# ATSAMRH707F18A device description
Architecture: CORTEX-M7; Family: SAMRH; Series: SAMRH707
Registers are 32-bit, read-write, no defined reset value unless marked. A register's access mark holds for its fields unless they carry their own. Offsets are from the block's base; [hi:lo] are bit positions; lines under a group give offsets from that group; {n}, {i} and the like mark numbered series; 'fields as' and 'values as' point back to an identical list.

## HSMC — Harden Static Memory Controller
Instances: HSMC 0x40081000
{0x0+0x10*i} HSMC_CS[{i}] (i=0..1) group
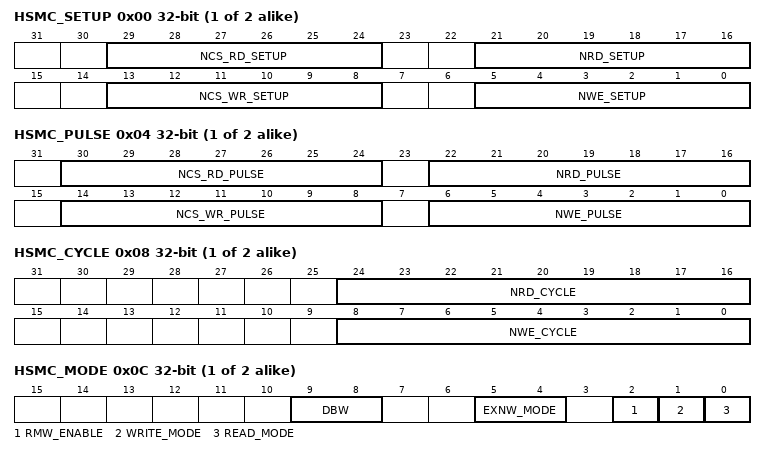
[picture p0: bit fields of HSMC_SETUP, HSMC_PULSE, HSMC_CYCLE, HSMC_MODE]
  0x00 HSMC_SETUP
    [29:24] NCS_RD_SETUP — NCS Setup Length in READ Access
    [21:16] NRD_SETUP — NRD Setup Length
    [13:8] NCS_WR_SETUP — NCS Setup Length in WRITE Access
    [5:0] NWE_SETUP — NWE Setup Length
  0x04 HSMC_PULSE
    [30:24] NCS_RD_PULSE — NCS Pulse Length in READ Access
    [22:16] NRD_PULSE — NRD Pulse Length
    [14:8] NCS_WR_PULSE — NCS Pulse Length in WRITE Access
    [6:0] NWE_PULSE — NWE Pulse Length
  0x08 HSMC_CYCLE
    [24:16] NRD_CYCLE — Total Read Cycle Length
    [8:0] NWE_CYCLE — Total Write Cycle Length
  0x0C HSMC_MODE
    [9:8] DBW — Data Bus Width
      0=_8_BIT (8-bit Data Bus)
    [5:4] EXNW_MODE — NWAIT Mode
      0=DISABLED (Disabled-The NWAIT input signal is ignored on the corresponding chip select.); 2=FROZEN (Frozen Mode-If asserted, the NWAIT signal freezes the current read or write cycle. After deassertion, the read/write cycle is resumed from the point where it was stopped.); 3=READY (Ready Mode-The NWAIT signal indicates the availability of the external device at the end of the pulse of the controlling read or write signal, to complete the access. If high, the access normally completes. If low, the access is extended until NWAIT returns high.)
    [2] RMW_ENABLE — Read-Modify Write enable
    [1] WRITE_MODE
    [0] READ_MODE
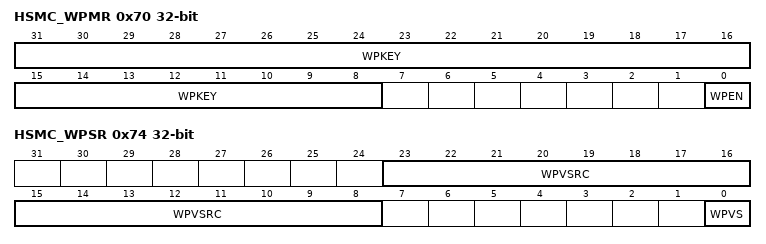
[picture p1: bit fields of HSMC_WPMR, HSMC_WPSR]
0x70 HSMC_WPMR — HSMC Write Protection Mode Register
  [31:8] WPKEY — Write Protection Key
    0x534D43=PASSWD (Writing any other value in this field aborts the write operation of the WPEN bit. Always reads as 0.)
  [0] WPEN — Write Protect Enable
0x74 HSMC_WPSR ro — HSMC Write Protection Status Register
  [23:8] WPVSRC — Write Protection Violation Source
  [0] WPVS — Write Protection Violation Status

## ICM_DESCRIPTOR — Region Descriptor Structure
0x00 RADDR — Region Start Address
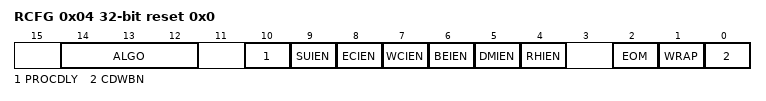
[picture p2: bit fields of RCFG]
0x04 RCFG reset 0x0 — Region Configuration
  [14:12] ALGO — SHA Algorithm
    0=SHA1 (SHA1 algorithm processed); 1=SHA256 (SHA256 algorithm processed); 4=SHA224 (SHA224 algorithm processed)
  [10] PROCDLY — SHA Processing Delay
    0=SHORT; 1=LONG
  [9] SUIEN — Region Status Updated Interrupt Enable
    0=EN; 1=DIS
  [8] ECIEN — Region End bit Condition detected Interrupt Enable
    0=EN; 1=DIS
  [7] WCIEN — Region Wrap Condition Detected Interrupt Enable
    0=EN; 1=DIS
  [6] BEIEN — Region Bus Error Interrupt Enable
    0=EN; 1=DIS
  [5] DMIEN — Region Digest Mismatch Interrupt Enable
    0=EN; 1=DIS
  [4] RHIEN — Region Hash Interrupt Enable
    0=EN; 1=DIS
  [2] EOM — End of Monitoring
    0=NO; 1=YES
  [1] WRAP — Region Wrap
    0=NO; 1=YES
  [0] CDWBN — Compare Digest Write Back
    0=WRBA; 1=COMP
0x08 RCTRL — Region Control
  [15:0] TRSIZE — Transfer Size for the Current Chunk of Data
0x0C RNEXT — Region Next Address
  [31:2] NEXT — Region Transfer Descriptor Next Address

## IP1553
Instances: IP1553 0x4003C000
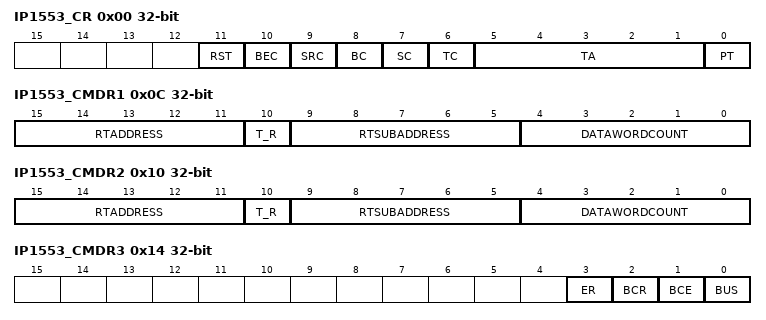
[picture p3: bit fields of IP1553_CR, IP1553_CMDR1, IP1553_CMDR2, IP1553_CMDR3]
0x00 IP1553_CR — Configuration Register
  [11] RST — Soft Reset
  [10] BEC — BCEnableCmd
  [9] SRC — SREQBitCmd
  [8] BC — BusyBitCmd
  [7] SC — SSBitCmd
  [6] TC — TRBitCmd
  [5:1] TA — TermAddressConf
  [0] PT — POTermConf
0x0C IP1553_CMDR1 wo — Command Register 1
  [15:11] RTADDRESS, [10] T_R, [9:5] RTSUBADDRESS, [4:0] DATAWORDCOUNT
0x10 IP1553_CMDR2 wo — Command Register 2
  [15:11] RTADDRESS
  [10] T_R — R/T
  [9:5] RTSUBADDRESS
  [4:0] DATAWORDCOUNT
0x14 IP1553_CMDR3 wo — Command Register 3
  [3] ER — data or command transfer
  [2] BCR — 1553 receiver
  [1] BCE — 1553 emitter
  [0] BUS — bus used
0x18 IP1553_BITR wo — BIT Register
  [15:0] TOBITWORD
0x1C IP1553_VWR wo — Vector Word Register
  [15:0] TOVECTORWORD
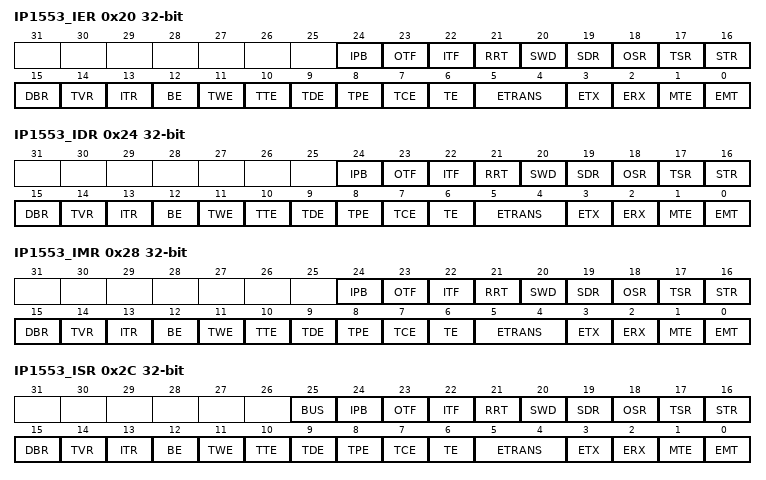
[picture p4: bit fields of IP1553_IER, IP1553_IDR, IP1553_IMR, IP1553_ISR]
0x20 IP1553_IER wo — IRQ Mask Enable Register
  [24] IPB — IPBusy
  [23] OTF — OvInhibitTermFlagReq
  [22] ITF — InhibitTermFlagReq
  [21] RRT — ResetRTReq
  [20] SWD — SyncWithoutDataReq
  [19] SDR — SyncWithDataReq
  [18] OSR — OvTranShutdownReq
  [17] TSR — TranShutdownReq
  [16] STR — InitSelfTestReq
  [15] DBR — DynamicBusContReq
  [14] TVR — TransVecWordReq
  [13] ITR — IllegalTransferReq
  [12] BE — BufIFErr
  [11] TWE — TransWordCounterErr
  [10] TTE — TransTimeOutErr
  [9] TDE — TransDataTypeErr
  [8] TPE — TransParityErr
  [7] TCE — TransCodingErr
  [6] TE — TransErr
  [5:4] ETRANS — EndTransfer
  [3] ETX — EndTransmission
  [2] ERX — End reception
  [1] MTE — MemTransferErr
  [0] EMT — EndMemTransfer
0x24 IP1553_IDR wo — IRQ Mask Disable Register
  fields as IP1553_IER
0x28 IP1553_IMR ro — IRQ Mask Register
  fields as IP1553_IER
0x2C IP1553_ISR ro — IRQ Status Register
  [25] BUS — BUS activated on last transfer
  [24] IPB — IPBusy
  [23] OTF — OvInhibitTermFlagReq
  [22] ITF — InhibitTermFlagReq
  [21] RRT — ResetRTReq
  [20] SWD — SyncWithoutDataReq
  [19] SDR — SyncWithDataReq
  [18] OSR — OvTranShutdownReq
  [17] TSR — TranShutdownReq
  [16] STR — InitSelfTestReq
  [15] DBR — DynamicBusContReq
  [14] TVR — TransVecWordReq
  [13] ITR — IllegalTransferReq
  [12] BE — BufIFErr
  [11] TWE — TransWordCounterErr
  [10] TTE — TransTimeOutErr
  [9] TDE — TransDataTypeErr
  [8] TPE — TransParityErr
  [7] TCE — TransCodingErr
  [6] TE — TransErr
  [5:4] ETRANS — EndTransfer
  [3] ETX — EndTransmission
  [2] ERX — End reception
  [1] MTE — MemTransferErr
  [0] EMT — EndMemTransfer
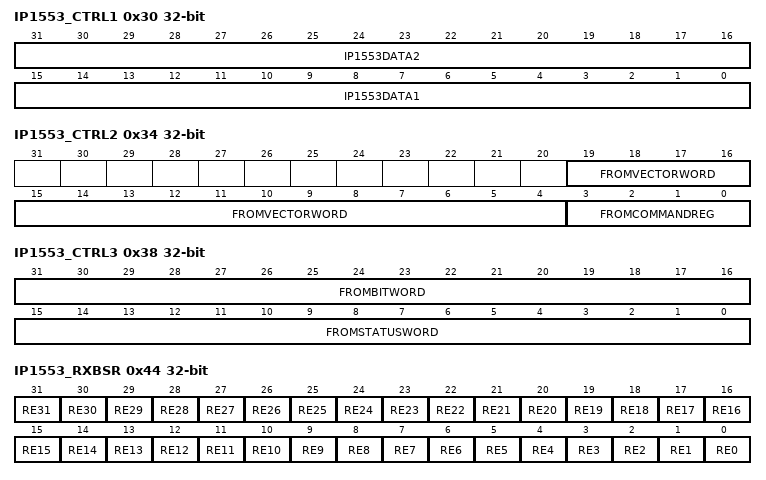
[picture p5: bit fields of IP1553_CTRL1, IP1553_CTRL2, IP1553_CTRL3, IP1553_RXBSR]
0x30 IP1553_CTRL1 ro — Control Register 1
  [31:16] IP1553DATA2 — IP1553 data value 2
  [15:0] IP1553DATA1 — IP1553 data value 1
0x34 IP1553_CTRL2 ro — Control Register 2
  [19:4] FROMVECTORWORD — from vector register
  [3:0] FROMCOMMANDREG — from command register
0x38 IP1553_CTRL3 ro — Control Register 3
  [31:16] FROMBITWORD — content of bit word register
  [15:0] FROMSTATUSWORD — content of status word register
0x3C IP1553_ARW — Address Register Write
  [31:0] REG_ADDR_APB_W — TX base address
0x40 IP1553_ARR — Address Register Read
  [31:0] REG_ADDR_APB_R — RX base address
0x44 IP1553_RXBSR — Rx Buffer Status Register
  [n] RE{n} (n=0..31) — Receive Buffer, {n} with x=[0-31]
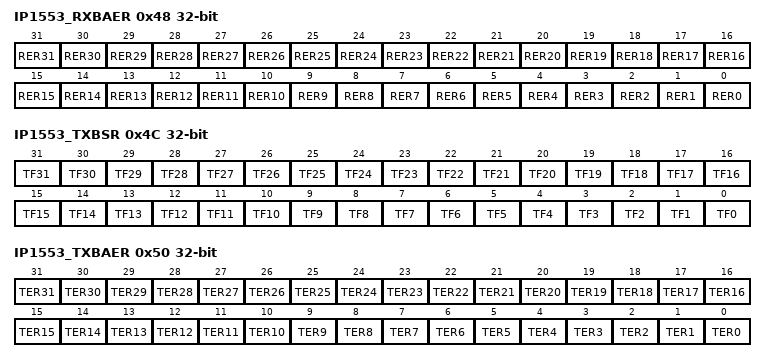
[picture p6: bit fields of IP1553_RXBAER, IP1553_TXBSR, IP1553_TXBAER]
0x48 IP1553_RXBAER — Rx Buffer Access Error Register
  [n] RER{n} (n=0..31) — Receive error {n}, x with x=[0-31]
0x4C IP1553_TXBSR — Tx Buffer Status Register
  [n] TF{n} (n=0..31) — Transmit buffer {n}, x with x=[0-31]
0x50 IP1553_TXBAER — Tx Buffer Access Error Register
  [n] TER{n} (n=0..31) — Transmit error {n}, x with x=[0-31]
